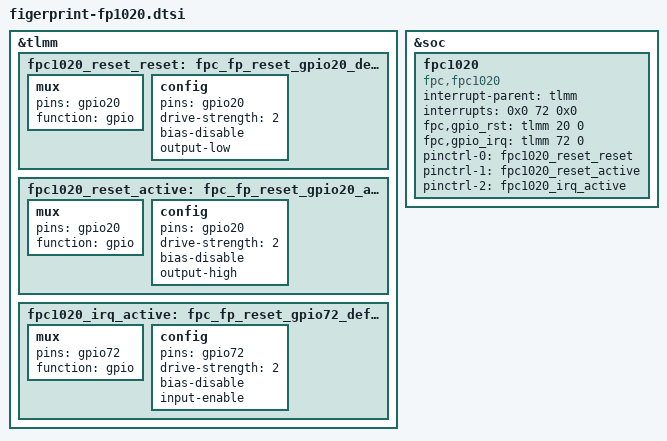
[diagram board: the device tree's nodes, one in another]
/* Copyright (c) 2016, The Linux Foundation. All rights reserved.
 *
 * This program is free software; you can redistribute it and/or modify
 * it under the terms of the GNU General Public License version 2 and
 * only version 2 as published by the Free Software Foundation.
 *
 * This program is distributed in the hope that it will be useful,
 * but WITHOUT ANY WARRANTY; without even the implied warranty of
 * MERCHANTABILITY or FITNESS FOR A PARTICULAR PURPOSE.  See the
 * GNU General Public License for more details.
 */

/*
 * SS2-fingerprint: fingerprint config
 */

&tlmm {
    fpc1020_reset_reset: fpc_fp_reset_gpio20_default {
        
            mux {
                pins = "gpio20";
                function = "gpio";
            };

            config{
                pins = "gpio20";
                drive-strength = <2>;
                bias-disable;
                output-low;
             };
        };

    fpc1020_reset_active: fpc_fp_reset_gpio20_active {

            mux {
                pins = "gpio20";
                function = "gpio";
            };

            config{
                pins = "gpio20";
                drive-strength = <2>;
                bias-disable;
                output-high;
            };
        };


     fpc1020_irq_active: fpc_fp_reset_gpio72_default {

            mux {
                pins = "gpio72";
                function = "gpio";
            };

            config{
                pins = "gpio72";
                drive-strength = <2>;
                     bias-disable;
                input-enable;
            };
        };
 
};

&soc {
    fpc1020 {
            compatible = "fpc,fpc1020";
            status = "ok";
            interrupt-parent  = <&tlmm>;
            interrupts        = <0x0 72 0x0>;
            fpc,gpio_rst = <&tlmm 20 0>;
            fpc,gpio_irq = <&tlmm 72 0>;
            pinctrl-names     =
                        "fpc1020_reset_reset",
                        "fpc1020_reset_active",
                        "fpc1020_irq_active";

            pinctrl-0         = <&fpc1020_reset_reset>;
            pinctrl-1         = <&fpc1020_reset_active>;
            pinctrl-2         = <&fpc1020_irq_active>;
    };
};
